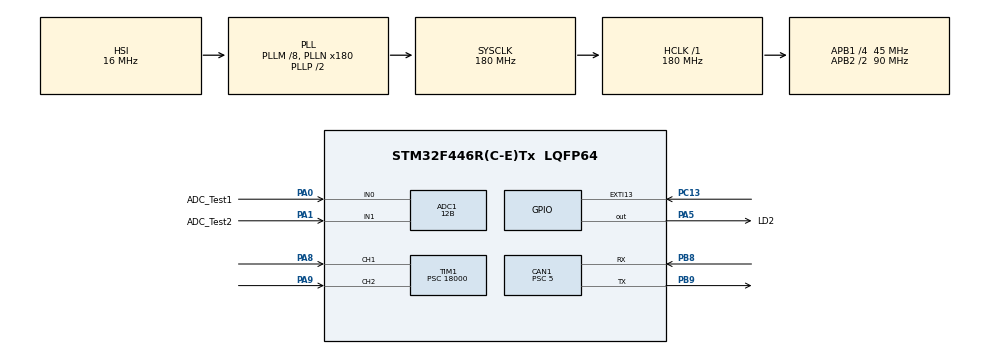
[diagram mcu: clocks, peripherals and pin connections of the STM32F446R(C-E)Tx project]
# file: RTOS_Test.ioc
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ADC1.Channel-4\#ChannelRegularConversion=ADC_CHANNEL_0
ADC1.Channel-5\#ChannelRegularConversion=ADC_CHANNEL_1
ADC1.ClockPrescaler=ADC_CLOCK_SYNC_PCLK_DIV4
ADC1.ContinuousConvMode=ENABLE
ADC1.DMAContinuousRequests=ENABLE
ADC1.DataAlign=ADC_DATAALIGN_RIGHT
ADC1.DiscontinuousConvMode=DISABLE
ADC1.EOCSelection=ADC_EOC_SEQ_CONV
ADC1.EnableAnalogWatchDog=false
ADC1.ExternalTrigConv=ADC_SOFTWARE_START
ADC1.ExternalTrigConvEdge=ADC_EXTERNALTRIGCONVEDGE_NONE
ADC1.InjNumberOfConversion=0
ADC1.NbrOfConversion=2
ADC1.NbrOfConversionFlag=1
ADC1.Rank-4\#ChannelRegularConversion=1
ADC1.Rank-5\#ChannelRegularConversion=2
ADC1.Resolution=ADC_RESOLUTION_12B
ADC1.SamplingTime-4\#ChannelRegularConversion=ADC_SAMPLETIME_3CYCLES
ADC1.SamplingTime-5\#ChannelRegularConversion=ADC_SAMPLETIME_3CYCLES
ADC1.ScanConvMode=ENABLE
ADC1.master=1
CAN1.BS1=CAN_BS1_15TQ
CAN1.BS2=CAN_BS2_2TQ
CAN1.CalculateTimeBit=2000
CAN1.CalculateTimeQuantum=111.11111111111111
CAN1.Mode=CAN_MODE_NORMAL
CAN1.Prescaler=5
CAN1.SJW=CAN_SJW_1TQ
Dma.ADC1.0.Direction=DMA_PERIPH_TO_MEMORY
Dma.ADC1.0.FIFOMode=DMA_FIFOMODE_DISABLE
Dma.ADC1.0.Instance=DMA2_Stream0
Dma.ADC1.0.MemDataAlignment=DMA_MDATAALIGN_HALFWORD
Dma.ADC1.0.MemInc=DMA_MINC_ENABLE
Dma.ADC1.0.Mode=DMA_CIRCULAR
Dma.ADC1.0.PeriphDataAlignment=DMA_PDATAALIGN_HALFWORD
Dma.ADC1.0.PeriphInc=DMA_PINC_DISABLE
Dma.ADC1.0.Priority=DMA_PRIORITY_HIGH
Dma.Request0=ADC1
FREERTOS.Tasks01=defaultTask,-3,128,StartDefaultTask,Default,NULL,Dynamic,NULL,NULL
Mcu.Family=STM32F4
Mcu.Name=STM32F446R(C-E)Tx
Mcu.Package=LQFP64
NVIC.CAN1_RX0_IRQn=true\:5\:0\:false\:false\:true\:true
NVIC.CAN1_RX1_IRQn=true\:5\:0\:false\:false\:true\:true
NVIC.DMA2_Stream0_IRQn=true\:5\:0\:false\:false\:true\:true
NVIC.PriorityGroup=NVIC_PRIORITYGROUP_4
NVIC.TIM1_CC_IRQn=true\:5\:0\:false\:false\:true\:true
PA0-WKUP.GPIO_Label=ADC_Test1
PA0-WKUP.Signal=ADCx_IN0
PA1.GPIO_Label=ADC_Test2
PA1.GPIO_PuPd=GPIO_NOPULL
PA1.Signal=ADCx_IN1
PA13.Mode=Serial_Wire
PA13.Signal=SYS_JTMS-SWDIO
PA14.Mode=Serial_Wire
PA14.Signal=SYS_JTCK-SWCLK
PA2.GPIO_Mode=GPIO_MODE_AF_PP
PA2.GPIO_PuPd=GPIO_NOPULL
PA2.GPIO_Speed=GPIO_SPEED_FREQ_VERY_HIGH
PA2.Signal=USART2_TX
PA3.GPIO_Mode=GPIO_MODE_AF_PP
PA3.GPIO_PuPd=GPIO_NOPULL
PA3.GPIO_Speed=GPIO_SPEED_FREQ_VERY_HIGH
PA3.Signal=USART2_RX
PA5.GPIO_Label=LD2
PA5.Signal=GPIO_Output
PA8.Signal=S_TIM1_CH1
PA9.Signal=S_TIM1_CH2
PB3.Signal=SYS_JTDO-SWO
PB8.Mode=Master
PB8.Signal=CAN1_RX
PB9.Mode=Master
PB9.Signal=CAN1_TX
PC13.GPIO_ModeDefaultEXTI=GPIO_MODE_IT_RISING
PC13.GPIO_PuPd=GPIO_NOPULL
PC13.Signal=GPXTI13
PC14-OSC32_IN.Signal=RCC_OSC32_IN
PC15-OSC32_OUT.Signal=RCC_OSC32_OUT
PH0-OSC_IN.Signal=RCC_OSC_IN
PH1-OSC_OUT.Signal=RCC_OSC_OUT
ProjectManager.HeapSize=0x200
ProjectManager.StackSize=0x400
ProjectManager.TargetToolchain=SW4STM32
RCC.AHBFreq_Value=180000000
RCC.APB1CLKDivider=RCC_HCLK_DIV4
RCC.APB1Freq_Value=45000000
RCC.APB1TimFreq_Value=90000000
RCC.APB2CLKDivider=RCC_HCLK_DIV2
RCC.APB2Freq_Value=90000000
RCC.APB2TimFreq_Value=180000000
RCC.CortexFreq_Value=180000000
RCC.FLatency-AdvancedSettings=FLASH_LATENCY_5
RCC.HCLKFreq_Value=180000000
RCC.HSE_VALUE=8000000
RCC.HSI_VALUE=16000000
RCC.LSE_VALUE=32768
RCC.PLLM=8
RCC.PLLN=180
RCC.SYSCLKFreq_VALUE=180000000
RCC.SYSCLKSource=RCC_SYSCLKSOURCE_PLLCLK
RCC.USBFreq_Value=180000000
RCC.VCOOutputFreq_Value=360000000
SH.ADCx_IN0.0=ADC1_IN0,IN0
SH.ADCx_IN1.0=ADC1_IN1,IN1
SH.S_TIM1_CH1.0=TIM1_CH1,Input_Capture1_from_TI1
SH.S_TIM1_CH2.0=TIM1_CH2,Input_Capture2_from_TI2
TIM1.Channel-Input_Capture1_from_TI1=TIM_CHANNEL_1
TIM1.Channel-Input_Capture2_from_TI2=TIM_CHANNEL_2
TIM1.Period=65535
TIM1.Prescaler=18000
VP_FREERTOS_VS_ENABLE.Mode=Enabled
board=NUCLEO-F446RE

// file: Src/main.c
/**
  ******************************************************************************
  * File Name          : main.c
  * Description        : Main program body
  ******************************************************************************
  * This notice applies to any and all portions of this file
  * that are not between comment pairs USER CODE BEGIN and
  * USER CODE END. Other portions of this file, whether
  * inserted by the user or by software development tools
  * are owned by their respective copyright owners.
  *
  * Copyright (c) 2017 STMicroelectronics International N.V.
  * All rights reserved.
  *
  * Redistribution and use in source and binary forms, with or without
  * modification, are permitted, provided that the following conditions are met:
  *
  * 1. Redistribution of source code must retain the above copyright notice,
  *    this list of conditions and the following disclaimer.
  * 2. Redistributions in binary form must reproduce the above copyright notice,
  *    this list of conditions and the following disclaimer in the documentation
  *    and/or other materials provided with the distribution.
  * 3. Neither the name of STMicroelectronics nor the names of other
  *    contributors to this software may be used to endorse or promote products
  *    derived from this software without specific written permission.
  * 4. This software, including modifications and/or derivative works of this
  *    software, must execute solely and exclusively on microcontroller or
  *    microprocessor devices manufactured by or for STMicroelectronics.
  * 5. Redistribution and use of this software other than as permitted under
  *    this license is void and will automatically terminate your rights under
  *    this license.
  *
  * THIS SOFTWARE IS PROVIDED BY STMICROELECTRONICS AND CONTRIBUTORS "AS IS"
  * AND ANY EXPRESS, IMPLIED OR STATUTORY WARRANTIES, INCLUDING, BUT NOT
  * LIMITED TO, THE IMPLIED WARRANTIES OF MERCHANTABILITY, FITNESS FOR A
  * PARTICULAR PURPOSE AND NON-INFRINGEMENT OF THIRD PARTY INTELLECTUAL PROPERTY
  * RIGHTS ARE DISCLAIMED TO THE FULLEST EXTENT PERMITTED BY LAW. IN NO EVENT
  * SHALL STMICROELECTRONICS OR CONTRIBUTORS BE LIABLE FOR ANY DIRECT, INDIRECT,
  * INCIDENTAL, SPECIAL, EXEMPLARY, OR CONSEQUENTIAL DAMAGES (INCLUDING, BUT NOT
  * LIMITED TO, PROCUREMENT OF SUBSTITUTE GOODS OR SERVICES; LOSS OF USE, DATA,
  * OR PROFITS; OR BUSINESS INTERRUPTION) HOWEVER CAUSED AND ON ANY THEORY OF
  * LIABILITY, WHETHER IN CONTRACT, STRICT LIABILITY, OR TORT (INCLUDING
  * NEGLIGENCE OR OTHERWISE) ARISING IN ANY WAY OUT OF THE USE OF THIS SOFTWARE,
  * EVEN IF ADVISED OF THE POSSIBILITY OF SUCH DAMAGE.
  *
  ******************************************************************************
  */
#include "main.h"
#include "stm32f4xx_hal.h"
#include "cmsis_os.h"

/* USER CODE BEGIN Includes */
#include "debug.h"
#include "led_flash_task.h"
#include "adc.h"
#include "ic.h"
#include "can.h"
/* USER CODE END Includes */

ADC_HandleTypeDef hadc1;
DMA_HandleTypeDef hdma_adc1;

CAN_HandleTypeDef hcan1;

TIM_HandleTypeDef htim1;

osThreadId defaultTaskHandle;

/* USER CODE BEGIN PV */
/* Private variables ---------------------------------------------------------*/

/* USER CODE END PV */

void SystemClock_Config(void);
static void MX_GPIO_Init(void);
static void MX_DMA_Init(void);
static void MX_ADC1_Init(void);
static void MX_TIM1_Init(void);
static void MX_CAN1_Init(void);
void StartDefaultTask(void const * argument);

/* USER CODE BEGIN PFP */
/* Private function prototypes -----------------------------------------------*/
/* USER CODE END PFP */

int main(void)
{

  /* MCU Configuration----------------------------------------------------------*/

  /* Reset of all peripherals, Initializes the Flash interface and the Systick. */
  HAL_Init();

  /* Configure the system clock */
  SystemClock_Config();

  /* Initialize all configured peripherals */
  MX_GPIO_Init();
  MX_DMA_Init();
  MX_ADC1_Init();
  MX_TIM1_Init();
  MX_CAN1_Init();

  /* USER CODE BEGIN 2 */
  debug_init();
  LED_Flash_Init();
//  ADC_Read_Init();
//  IC_Init();
  debug_log("<<< Init Finished >>>");
  /* USER CODE END 2 */

  /* Create the thread(s) */
  /* definition and creation of defaultTask */
  osThreadDef(defaultTask, StartDefaultTask, osPriorityIdle, 0, 128);
  defaultTaskHandle = osThreadCreate(osThread(defaultTask), NULL);

  /* USER CODE BEGIN RTOS_THREADS */
  osThreadDef(ledTask, LED_Flash_Start, osPriorityNormal, 0, 128);
  osThreadCreate(osThread(ledTask), NULL);

//  osThreadDef(adcTask, ADC_Read_Start, osPriorityNormal, 0, 128);
//  osThreadCreate(osThread(adcTask), NULL);

//  osThreadDef(icTask, IC_Report_Start, osPriorityNormal, 0, 128);
//  osThreadCreate(osThread(icTask), NULL);

//  osThreadDef(canTask, Can_Send_Start, osPriorityNormal, 0, 128);
//  osThreadCreate(osThread(canTask), NULL);

    osThreadDef(canTask, Can_Recieve_Start, osPriorityNormal, 0, 128);
    osThreadCreate(osThread(canTask), NULL);
  /* USER CODE END RTOS_THREADS */

  /* Start scheduler */
  osKernelStart();

  /* We should never get here as control is now taken by the scheduler */

  /* Infinite loop */
  while (1)
  {

  }

}

/** System Clock Configuration
*/
void SystemClock_Config(void)
{

  RCC_OscInitTypeDef RCC_OscInitStruct;
  RCC_ClkInitTypeDef RCC_ClkInitStruct;

    /**Configure the main internal regulator output voltage
    */
  __HAL_RCC_PWR_CLK_ENABLE();

  __HAL_PWR_VOLTAGESCALING_CONFIG(PWR_REGULATOR_VOLTAGE_SCALE1);

    /**Initializes the CPU, AHB and APB busses clocks
    */
  RCC_OscInitStruct.OscillatorType = RCC_OSCILLATORTYPE_HSI;
  RCC_OscInitStruct.HSIState = RCC_HSI_ON;
  RCC_OscInitStruct.HSICalibrationValue = 16;
  RCC_OscInitStruct.PLL.PLLState = RCC_PLL_ON;
  RCC_OscInitStruct.PLL.PLLSource = RCC_PLLSOURCE_HSI;
  RCC_OscInitStruct.PLL.PLLM = 8;
  RCC_OscInitStruct.PLL.PLLN = 180;
  RCC_OscInitStruct.PLL.PLLP = RCC_PLLP_DIV2;
  RCC_OscInitStruct.PLL.PLLQ = 2;
  RCC_OscInitStruct.PLL.PLLR = 2;
  if (HAL_RCC_OscConfig(&RCC_OscInitStruct) != HAL_OK)
  {
    _Error_Handler(__FILE__, __LINE__);
  }

    /**Activate the Over-Drive mode
    */
  if (HAL_PWREx_EnableOverDrive() != HAL_OK)
  {
    _Error_Handler(__FILE__, __LINE__);
  }

    /**Initializes the CPU, AHB and APB busses clocks
    */
  RCC_ClkInitStruct.ClockType = RCC_CLOCKTYPE_HCLK|RCC_CLOCKTYPE_SYSCLK
                              |RCC_CLOCKTYPE_PCLK1|RCC_CLOCKTYPE_PCLK2;
  RCC_ClkInitStruct.SYSCLKSource = RCC_SYSCLKSOURCE_PLLCLK;
  RCC_ClkInitStruct.AHBCLKDivider = RCC_SYSCLK_DIV1;
  RCC_ClkInitStruct.APB1CLKDivider = RCC_HCLK_DIV4;
  RCC_ClkInitStruct.APB2CLKDivider = RCC_HCLK_DIV2;

  if (HAL_RCC_ClockConfig(&RCC_ClkInitStruct, FLASH_LATENCY_5) != HAL_OK)
  {
    _Error_Handler(__FILE__, __LINE__);
  }

    /**Configure the Systick interrupt time
    */
  HAL_SYSTICK_Config(HAL_RCC_GetHCLKFreq()/1000);

    /**Configure the Systick
    */
  HAL_SYSTICK_CLKSourceConfig(SYSTICK_CLKSOURCE_HCLK);

  /* SysTick_IRQn interrupt configuration */
  HAL_NVIC_SetPriority(SysTick_IRQn, 15, 0);
}

/* ADC1 init function */
static void MX_ADC1_Init(void)
{

  ADC_ChannelConfTypeDef sConfig;

    /**Configure the global features of the ADC (Clock, Resolution, Data Alignment and number of conversion)
    */
  hadc1.Instance = ADC1;
  hadc1.Init.ClockPrescaler = ADC_CLOCK_SYNC_PCLK_DIV4;
  hadc1.Init.Resolution = ADC_RESOLUTION_12B;
  hadc1.Init.ScanConvMode = ENABLE;
  hadc1.Init.ContinuousConvMode = ENABLE;
  hadc1.Init.DiscontinuousConvMode = DISABLE;
  hadc1.Init.ExternalTrigConvEdge = ADC_EXTERNALTRIGCONVEDGE_NONE;
  hadc1.Init.ExternalTrigConv = ADC_SOFTWARE_START;
  hadc1.Init.DataAlign = ADC_DATAALIGN_RIGHT;
  hadc1.Init.NbrOfConversion = 2;
  hadc1.Init.DMAContinuousRequests = ENABLE;
  hadc1.Init.EOCSelection = ADC_EOC_SEQ_CONV;
  if (HAL_ADC_Init(&hadc1) != HAL_OK)
  {
    _Error_Handler(__FILE__, __LINE__);
  }

    /**Configure for the selected ADC regular channel its corresponding rank in the sequencer and its sample time.
    */
  sConfig.Channel = ADC_CHANNEL_0;
  sConfig.Rank = 1;
  sConfig.SamplingTime = ADC_SAMPLETIME_3CYCLES;
  if (HAL_ADC_ConfigChannel(&hadc1, &sConfig) != HAL_OK)
  {
    _Error_Handler(__FILE__, __LINE__);
  }

    /**Configure for the selected ADC regular channel its corresponding rank in the sequencer and its sample time.
    */
  sConfig.Channel = ADC_CHANNEL_1;
  sConfig.Rank = 2;
  if (HAL_ADC_ConfigChannel(&hadc1, &sConfig) != HAL_OK)
  {
    _Error_Handler(__FILE__, __LINE__);
  }

}

/* CAN1 init function */
static void MX_CAN1_Init(void)
{

  hcan1.Instance = CAN1;
  hcan1.Init.Prescaler = 5;
  hcan1.Init.Mode = CAN_MODE_NORMAL;
  hcan1.Init.SJW = CAN_SJW_1TQ;
  hcan1.Init.BS1 = CAN_BS1_15TQ;
  hcan1.Init.BS2 = CAN_BS2_2TQ;
  hcan1.Init.TTCM = DISABLE;
  hcan1.Init.ABOM = DISABLE;
  hcan1.Init.AWUM = DISABLE;
  hcan1.Init.NART = DISABLE;
  hcan1.Init.RFLM = DISABLE;
  hcan1.Init.TXFP = DISABLE;
  if (HAL_CAN_Init(&hcan1) != HAL_OK)
  {
    _Error_Handler(__FILE__, __LINE__);
  }

}

/* TIM1 init function */
static void MX_TIM1_Init(void)
{

  TIM_MasterConfigTypeDef sMasterConfig;
  TIM_IC_InitTypeDef sConfigIC;

  htim1.Instance = TIM1;
  htim1.Init.Prescaler = 18000;
  htim1.Init.CounterMode = TIM_COUNTERMODE_UP;
  htim1.Init.Period = 65535;
  htim1.Init.ClockDivision = TIM_CLOCKDIVISION_DIV1;
  htim1.Init.RepetitionCounter = 0;
  if (HAL_TIM_IC_Init(&htim1) != HAL_OK)
  {
    _Error_Handler(__FILE__, __LINE__);
  }

  sMasterConfig.MasterOutputTrigger = TIM_TRGO_RESET;
  sMasterConfig.MasterSlaveMode = TIM_MASTERSLAVEMODE_DISABLE;
  if (HAL_TIMEx_MasterConfigSynchronization(&htim1, &sMasterConfig) != HAL_OK)
  {
    _Error_Handler(__FILE__, __LINE__);
  }

  sConfigIC.ICPolarity = TIM_INPUTCHANNELPOLARITY_RISING;
  sConfigIC.ICSelection = TIM_ICSELECTION_DIRECTTI;
  sConfigIC.ICPrescaler = TIM_ICPSC_DIV1;
  sConfigIC.ICFilter = 0;
  if (HAL_TIM_IC_ConfigChannel(&htim1, &sConfigIC, TIM_CHANNEL_1) != HAL_OK)
  {
    _Error_Handler(__FILE__, __LINE__);
  }

  if (HAL_TIM_IC_ConfigChannel(&htim1, &sConfigIC, TIM_CHANNEL_2) != HAL_OK)
  {
    _Error_Handler(__FILE__, __LINE__);
  }

}

static void MX_DMA_Init(void)
{
  /* DMA controller clock enable */
  __HAL_RCC_DMA2_CLK_ENABLE();

  /* DMA interrupt init */
  /* DMA2_Stream0_IRQn interrupt configuration */
  HAL_NVIC_SetPriority(DMA2_Stream0_IRQn, 5, 0);
  HAL_NVIC_EnableIRQ(DMA2_Stream0_IRQn);

}

/** Configure pins as
        * Analog
        * Input
        * Output
        * EVENT_OUT
        * EXTI
     PA2   ------> USART2_TX
     PA3   ------> USART2_RX
*/
static void MX_GPIO_Init(void)
{

  GPIO_InitTypeDef GPIO_InitStruct;

  /* GPIO Ports Clock Enable */
  __HAL_RCC_GPIOC_CLK_ENABLE();
  __HAL_RCC_GPIOH_CLK_ENABLE();
  __HAL_RCC_GPIOA_CLK_ENABLE();
  __HAL_RCC_GPIOB_CLK_ENABLE();

  /*Configure GPIO pin Output Level */
  HAL_GPIO_WritePin(LD2_GPIO_Port, LD2_Pin, GPIO_PIN_RESET);

  /*Configure GPIO pin : PC13 */
  GPIO_InitStruct.Pin = GPIO_PIN_13;
  GPIO_InitStruct.Mode = GPIO_MODE_IT_RISING;
  GPIO_InitStruct.Pull = GPIO_NOPULL;
  HAL_GPIO_Init(GPIOC, &GPIO_InitStruct);

  /*Configure GPIO pins : PA2 PA3 */
  GPIO_InitStruct.Pin = GPIO_PIN_2|GPIO_PIN_3;
  GPIO_InitStruct.Mode = GPIO_MODE_AF_PP;
  GPIO_InitStruct.Pull = GPIO_NOPULL;
  GPIO_InitStruct.Speed = GPIO_SPEED_FREQ_VERY_HIGH;
  GPIO_InitStruct.Alternate = GPIO_AF7_USART2;
  HAL_GPIO_Init(GPIOA, &GPIO_InitStruct);

  /*Configure GPIO pin : LD2_Pin */
  GPIO_InitStruct.Pin = LD2_Pin;
  GPIO_InitStruct.Mode = GPIO_MODE_OUTPUT_PP;
  GPIO_InitStruct.Pull = GPIO_NOPULL;
  GPIO_InitStruct.Speed = GPIO_SPEED_FREQ_LOW;
  HAL_GPIO_Init(LD2_GPIO_Port, &GPIO_InitStruct);

}

/* StartDefaultTask function */
void StartDefaultTask(void const * argument)
{

  for(;;)
  {
    osDelay(1);
  }
}

void _Error_Handler(char * file, int line)
{
  /* USER CODE BEGIN Error_Handler_Debug */
  /* User can add his own implementation to report the HAL error return state */
  debug_log("[Critical Error]: %s:%d", file, line);
  while(1)
  {
  }
  /* USER CODE END Error_Handler_Debug */
}

/************************ (C) COPYRIGHT STMicroelectronics *****END OF FILE****/
